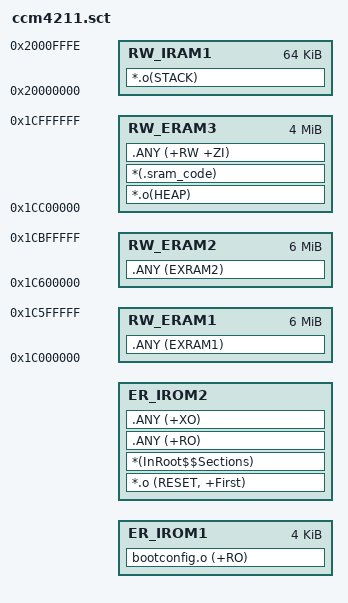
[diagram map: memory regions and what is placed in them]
#!armclang --target=arm-arm-none-eabi -mcpu=cortex-m7 -E -x c
; *************************************************************
; *** Scatter-Loading Description File generated by uVision ***
; *************************************************************
#include "../Src/src/sys/inc/chipconfig.h"
	
LR_IROM1 START_CONFIG_ADDR SSI_LENGTH  {    ; load region size_region
ER_IROM1 START_CONFIG_ADDR 0x00001000  {  ; load address = execution address
   bootconfig.o (+RO)
}

ER_IROM2 START_USER_ADDR SSI_LENGTH-0x1000  {  ; load address = execution address
   *.o (RESET, +First)
   *(InRoot$$Sections)
   .ANY (+RO)
   .ANY (+XO)
  }
  RW_IRAM1 0x20000000 0x0ffff  {  ; RW data
   *.o(STACK)
  }
  RW_ERAM1 0x1c000000   0x00600000 { ; 外部PSRAM
    .ANY (EXRAM1)
  }

  RW_ERAM2 0x1c600000   0x00600000 { ; 外部PSRAM
    .ANY (EXRAM2)
  }

  RW_ERAM3 0x1cc00000   0x00400000 { ; 外部PSRAM
	*.o(HEAP)
   *(.sram_code)
	.ANY (+RW +ZI)
  }

}
